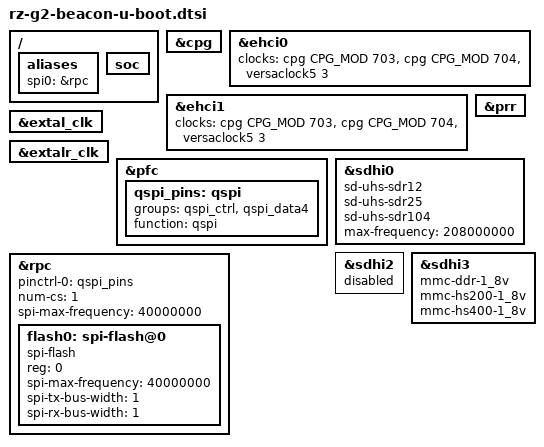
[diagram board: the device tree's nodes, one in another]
// SPDX-License-Identifier: GPL-2.0
/*
 * Copyright 2021 LogicPD dba Beacon EmbeddedWorks
 */

/ {
	aliases {
		spi0 = &rpc;
	};

	soc {
		bootph-all;
	};
};

&cpg {
	bootph-all;
};

&ehci0 {
	clocks = <&cpg CPG_MOD 703>, <&cpg CPG_MOD 704>, <&versaclock5 3>;
};

&ehci1 {
	clocks = <&cpg CPG_MOD 703>, <&cpg CPG_MOD 704>, <&versaclock5 3>;
};

&extal_clk {
	bootph-all;
};

&extalr_clk {
	bootph-all;
};

&pfc {
	qspi_pins: qspi {
		groups = "qspi_ctrl", "qspi_data4";
		function = "qspi";
	};
};

&prr {
	bootph-all;
};

&rpc {
	pinctrl-0 = <&qspi_pins>;
	pinctrl-names = "default";
	num-cs = <1>;
	spi-max-frequency = <40000000>;
	#address-cells = <1>;
	#size-cells = <0>;
	status = "okay";

	flash0: spi-flash@0 {
		#address-cells = <1>;
		#size-cells = <1>;
		reg = <0>;
		compatible = "spi-flash", "jedec,spi-nor";
		spi-max-frequency = <40000000>;
		spi-tx-bus-width = <1>;
		spi-rx-bus-width = <1>;
	};
};

&sdhi0 {
	/delete-property/ cd-gpios;
	sd-uhs-sdr12;
	sd-uhs-sdr25;
	sd-uhs-sdr104;
	max-frequency = <208000000>;
};

&sdhi2 {
	status = "disabled";
};

&sdhi3 {
	mmc-ddr-1_8v;
	mmc-hs200-1_8v;
	mmc-hs400-1_8v;
};
